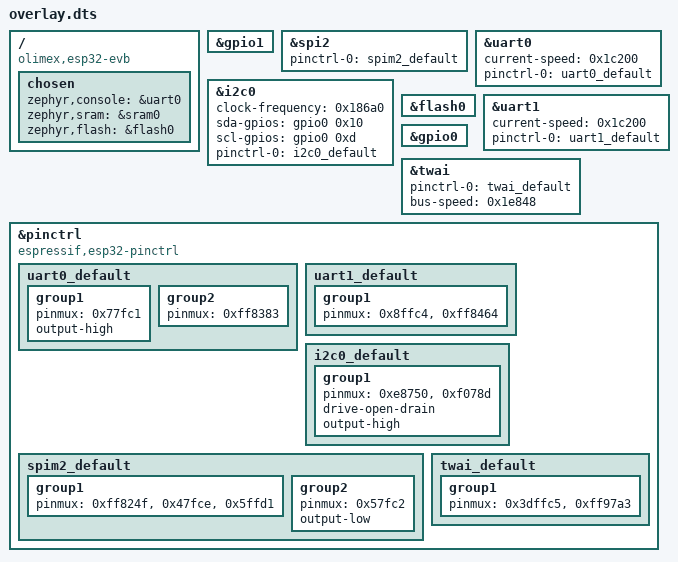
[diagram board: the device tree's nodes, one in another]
/ {
	compatible = "olimex,esp32-evb", "espressif,esp32-wroom-32e", "espressif,esp32";
	chosen {
		zephyr,console = &uart0;
		zephyr,sram = &sram0;
		zephyr,flash = &flash0;
	};
};
&gpio1{
	status = "okay";
};
&spi2{
	status = "okay";
	pinctrl-0 = < &spim2_default >;
	pinctrl-names = "default";
	#address-cells = < 0x1 >;
	#size-cells = < 0x0 >;
};
&uart0{
	status = "okay";
	current-speed = < 0x1c200 >;
	pinctrl-0 = < &uart0_default >;
	pinctrl-names = "default";
};
&i2c0{
	status = "okay";
	clock-frequency = < 0x186a0 >;
	sda-gpios = < &gpio0 0x10 0x6 >;
	scl-gpios = < &gpio0 0xd 0x6 >;
	pinctrl-0 = < &i2c0_default >;
	pinctrl-names = "default";
};
&flash0{
	status = "okay";
};
&uart1{
	status = "okay";
	current-speed = < 0x1c200 >;
	pinctrl-0 = < &uart1_default >;
	pinctrl-names = "default";
};
&gpio0{
	status = "okay";
};
&twai{
	status = "okay";
	pinctrl-0 = < &twai_default >;
	pinctrl-names = "default";
	bus-speed = < 0x1e848 >;
};
&pinctrl{
	compatible = "espressif,esp32-pinctrl";
	status = "okay";
	uart0_default: uart0_default {
		group1 {
			pinmux = < 0x77fc1 >;
			output-high;
		};
		group2 {
			pinmux = < 0xff8383 >;
		};
	};
	uart1_default: uart1_default {
		group1 {
			pinmux = < 0x8ffc4 >, < 0xff8464 >;
		};
	};
	i2c0_default: i2c0_default {
		group1 {
			pinmux = < 0xe8750 >, < 0xf078d >;
			drive-open-drain;
			output-high;
		};
	};
	spim2_default: spim2_default {
		group1 {
			pinmux = < 0xff824f >, < 0x47fce >, < 0x5ffd1 >;
		};
		group2 {
			pinmux = < 0x57fc2 >;
			output-low;
		};
	};
	twai_default: twai_default {
		group1 {
			pinmux = < 0x3dffc5 >, < 0xff97a3 >;
		};
	};
};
